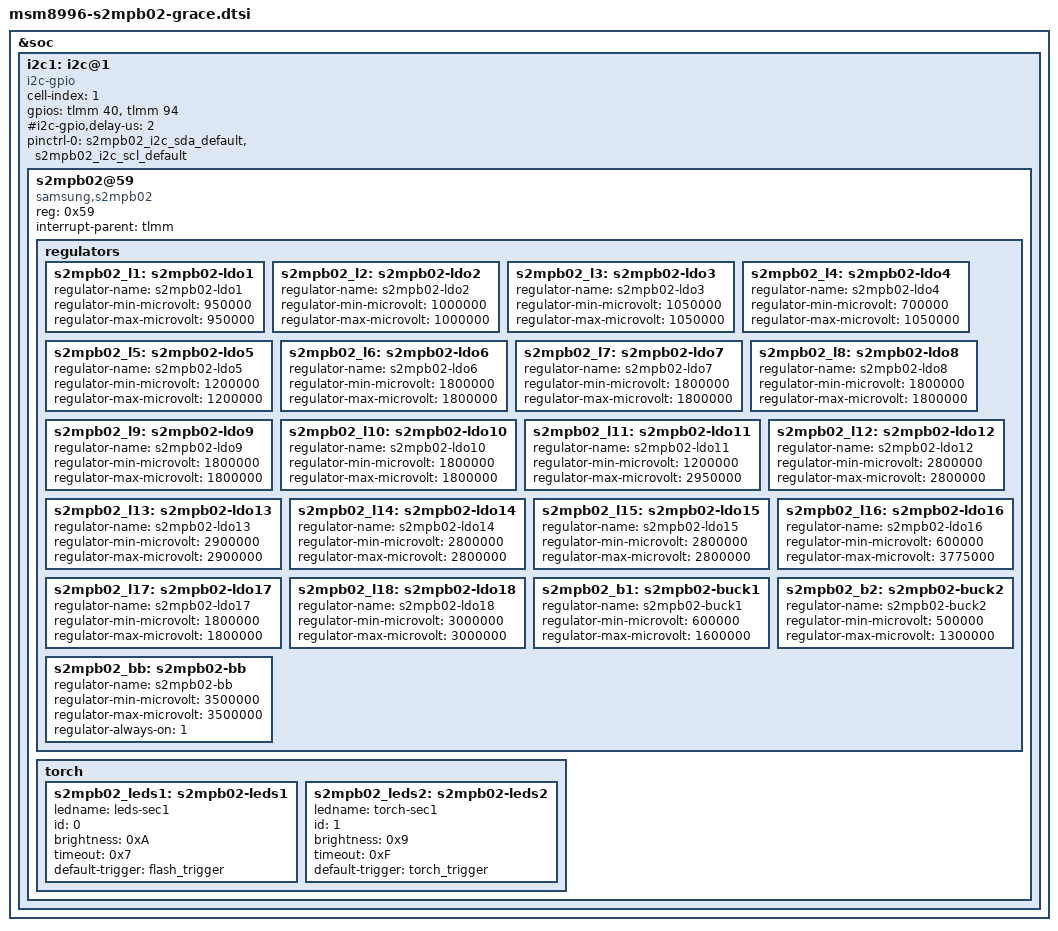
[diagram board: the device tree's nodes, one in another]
/* Copyright (c) 2012, The Linux Foundation. All rights reserved.
 *
 * This program is free software; you can redistribute it and/or modify
 * it under the terms of the GNU General Public License version 2 and
 * only version 2 as published by the Free Software Foundation.
 *
 * This program is distributed in the hope that it will be useful,
 * but WITHOUT ANY WARRANTY; without even the implied warranty of
 * MERCHANTABILITY or FITNESS FOR A PARTICULAR PURPOSE.  See the
 * GNU General Public License for more details.
 */


&soc {
	i2c1: i2c@1 {
		cell-index = <1>;
		compatible = "i2c-gpio";
		gpios = <&tlmm 40 0
			&tlmm 94 0
		>;
		#i2c-gpio,delay-us = <2>;
		#address-cells = <1>;
		#size-cells = <0>;

		pinctrl-names = "default";
		pinctrl-0 = <&s2mpb02_i2c_sda_default &s2mpb02_i2c_scl_default>;

		s2mpb02@59 {
			compatible = "samsung,s2mpb02";
			reg = <0x59>;
			interrupt-parent = <&tlmm>;
			status = "okay";

			regulators {
				s2mpb02_l1: s2mpb02-ldo1 {
					regulator-name = "s2mpb02-ldo1";
					regulator-min-microvolt = <950000>;
					regulator-max-microvolt = <950000>;
				};

				s2mpb02_l2: s2mpb02-ldo2 {
					regulator-name = "s2mpb02-ldo2";
					regulator-min-microvolt = <1000000>;
					regulator-max-microvolt = <1000000>;
				};

				s2mpb02_l3: s2mpb02-ldo3 {
					regulator-name = "s2mpb02-ldo3";
					regulator-min-microvolt = <1050000>;
					regulator-max-microvolt = <1050000>;
				};

				s2mpb02_l4: s2mpb02-ldo4 {
					regulator-name = "s2mpb02-ldo4";
					regulator-min-microvolt = <700000>;
					regulator-max-microvolt = <1050000>;
				};

				s2mpb02_l5: s2mpb02-ldo5 {
					regulator-name = "s2mpb02-ldo5";
					regulator-min-microvolt = <1200000>;
					regulator-max-microvolt = <1200000>;
				};

				s2mpb02_l6: s2mpb02-ldo6 {
					regulator-name = "s2mpb02-ldo6";
					regulator-min-microvolt = <1800000>;
					regulator-max-microvolt = <1800000>;
				};

				s2mpb02_l7: s2mpb02-ldo7 {
					regulator-name = "s2mpb02-ldo7";
					regulator-min-microvolt = <1800000>;
					regulator-max-microvolt = <1800000>;
				};

				s2mpb02_l8: s2mpb02-ldo8 {
					regulator-name = "s2mpb02-ldo8";
					regulator-min-microvolt = <1800000>;
					regulator-max-microvolt = <1800000>;
				};

				s2mpb02_l9: s2mpb02-ldo9 {
					regulator-name = "s2mpb02-ldo9";
					regulator-min-microvolt = <1800000>;
					regulator-max-microvolt = <1800000>;
				};

				s2mpb02_l10: s2mpb02-ldo10 {
					regulator-name = "s2mpb02-ldo10";
					regulator-min-microvolt = <1800000>;
					regulator-max-microvolt = <1800000>;
				};

				s2mpb02_l11: s2mpb02-ldo11 {
					regulator-name = "s2mpb02-ldo11";
					regulator-min-microvolt = <1200000>;
					regulator-max-microvolt = <2950000>;
				};

				s2mpb02_l12: s2mpb02-ldo12 {
					regulator-name = "s2mpb02-ldo12";
					regulator-min-microvolt = <2800000>;
					regulator-max-microvolt = <2800000>;
				};

				s2mpb02_l13: s2mpb02-ldo13 {
					regulator-name = "s2mpb02-ldo13";
					regulator-min-microvolt = <2900000>;
					regulator-max-microvolt = <2900000>;
				};

				s2mpb02_l14: s2mpb02-ldo14 {
					regulator-name = "s2mpb02-ldo14";
					regulator-min-microvolt = <2800000>;
					regulator-max-microvolt = <2800000>;
				};

				s2mpb02_l15: s2mpb02-ldo15 {
					regulator-name = "s2mpb02-ldo15";
					regulator-min-microvolt = <2800000>;
					regulator-max-microvolt = <2800000>;
				};

				s2mpb02_l16: s2mpb02-ldo16 {
					regulator-name = "s2mpb02-ldo16";
					regulator-min-microvolt = <600000>;
					regulator-max-microvolt = <3775000>;
				};

				s2mpb02_l17: s2mpb02-ldo17 {
					regulator-name = "s2mpb02-ldo17";
					regulator-min-microvolt = <1800000>;
					regulator-max-microvolt = <1800000>;
				};

				s2mpb02_l18: s2mpb02-ldo18 {
					regulator-name = "s2mpb02-ldo18";
					regulator-min-microvolt = <3000000>;
					regulator-max-microvolt = <3000000>;
				};

				s2mpb02_b1: s2mpb02-buck1 {
					regulator-name = "s2mpb02-buck1";
					regulator-min-microvolt = <600000>;
					regulator-max-microvolt = <1600000>;
				};

				s2mpb02_b2: s2mpb02-buck2 {
					regulator-name = "s2mpb02-buck2";
					regulator-min-microvolt = <500000>;
					regulator-max-microvolt = <1300000>;
				};

				s2mpb02_bb: s2mpb02-bb {
					regulator-name = "s2mpb02-bb";
					regulator-min-microvolt = <3500000>;
					regulator-max-microvolt = <3500000>;
					regulator-always-on = <1>;
				};
			};

			torch {
				status = "okay";
				s2mpb02_leds1: s2mpb02-leds1 {
					ledname = "leds-sec1";
					/* S2MPB02_FLASH_LED_1 */
					id = <0>;
					/* S2MPB02_FLASH_CURRENT */
					brightness = <0xA>;
					/* S2MPB02_FLASH_TIMEOUT */
					timeout = <0x7>;
					default-trigger = "flash_trigger";
				};

				s2mpb02_leds2: s2mpb02-leds2 {
					ledname = "torch-sec1";
					/* S2MPB02_TORCH_LED_1 */
					id = <1>;
					/* S2MPB02_TORCH_CURRENT */
					brightness = <0x9>;
					/* S2MPB02_TORCH_TIMEOUT */
					timeout = <0xF>;
					default-trigger = "torch_trigger";
				};
			};
		};
	};
};
